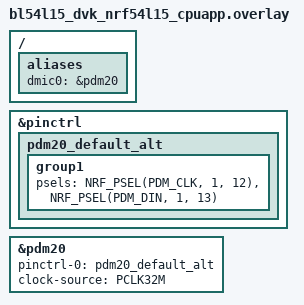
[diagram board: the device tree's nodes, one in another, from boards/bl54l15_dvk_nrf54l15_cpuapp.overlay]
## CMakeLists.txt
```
# SPDX-License-Identifier: Apache-2.0

cmake_minimum_required(VERSION 3.28.0)
find_package(Zephyr REQUIRED HINTS $ENV{ZEPHYR_BASE})
project(dmic_api)

FILE(GLOB app_sources src/*.c)
target_sources(app PRIVATE ${app_sources})
```

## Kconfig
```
# Copyright 2025 NXP
# SPDX-License-Identifier: Apache-2.0

source "Kconfig.zephyr"

config SAMPLE_BIT_WIDTH
	int "Sample bit width"
	default 32 if DT_HAS_NXP_MICFIL_ENABLED
	default 16
	help
	  PCM sample bit width.

config SAMPLE_PDM_CHANNELS
	int "Number of DMIC channels"
	default 4 if DT_HAS_NXP_MICFIL_ENABLED || DT_HAS_NXP_DMIC_ENABLED
	default 1 if DT_HAS_RENESAS_RA_PDM_ENABLED
	default 2
	help
	  Count of DMIC channels to capture and process. With 1, the stereo
	  test is skipped.

config TEST_HW_CHANNEL_INDEX
	int "hardware controller index"
	default 0
	help
	  Specifies the index of the hardware controller.

config TEST_SMALL_BUFFER
	bool "Use a smaller buffer for testing"
	default y if DT_HAS_RENESAS_RA_PDM_ENABLED
	help
	  Use a smaller buffer for testing. This is useful if your device has limited memory.
```

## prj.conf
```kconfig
CONFIG_TEST=y
CONFIG_ZTEST=y
CONFIG_AUDIO=y
CONFIG_AUDIO_DMIC=y

# Use deferred logging mode so the TC_PRINT calls while reading from DMIC
# do not block
CONFIG_LOG=y
CONFIG_LOG_MODE_DEFERRED=y
```

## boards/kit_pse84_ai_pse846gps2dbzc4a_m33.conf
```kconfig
# SPDX-FileCopyrightText: <text>Copyright (c) 2026 Infineon Technologies AG,
# or an affiliate of Infineon Technologies AG. All rights reserved.</text>
#
# SPDX-License-Identifier: Apache-2.0

CONFIG_TEST_HW_CHANNEL_INDEX=1
CONFIG_TEST_SMALL_BUFFER=y
```

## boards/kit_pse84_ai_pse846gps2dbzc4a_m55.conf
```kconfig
# SPDX-FileCopyrightText: Copyright (c) 2026 Infineon Technologies AG,
# SPDX-FileCopyrightText: or an affiliate of Infineon Technologies AG. All rights reserved.
#
# SPDX-License-Identifier: Apache-2.0

CONFIG_TEST_HW_CHANNEL_INDEX=1
```

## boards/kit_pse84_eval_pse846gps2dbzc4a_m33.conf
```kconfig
# SPDX-FileCopyrightText: Copyright (c) 2026 Infineon Technologies AG,
# SPDX-FileCopyrightText: or an affiliate of Infineon Technologies AG. All rights reserved.
#
# SPDX-License-Identifier: Apache-2.0

CONFIG_TEST_HW_CHANNEL_INDEX=1
CONFIG_TEST_SMALL_BUFFER=y
```

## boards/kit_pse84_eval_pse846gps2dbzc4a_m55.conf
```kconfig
# SPDX-FileCopyrightText: <text>Copyright (c) 2026 Infineon Technologies AG,
# or an affiliate of Infineon Technologies AG. All rights reserved.</text>
#
# SPDX-License-Identifier: Apache-2.0

CONFIG_TEST_HW_CHANNEL_INDEX=1
```

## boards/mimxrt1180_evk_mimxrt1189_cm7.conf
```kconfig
# SPDX-FileCopyrightText: Copyright 2026 NXP
# SPDX-License-Identifier: Apache-2.0

# The default buffers do not fit in the 256 KB DTCM
CONFIG_TEST_SMALL_BUFFER=y
```

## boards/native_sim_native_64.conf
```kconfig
# Copyright 2026 NXP
# SPDX-License-Identifier: Apache-2.0

CONFIG_AUDIO_DMIC_NATIVE_SIM=y
CONFIG_AUDIO_DMIC_NATIVE_SIM_FILE_PATH="/tmp/native_sim_dmic_in.pcm"
CONFIG_SAMPLE_BIT_WIDTH=16
CONFIG_SAMPLE_PDM_CHANNELS=2
CONFIG_TEST_HW_CHANNEL_INDEX=0
```

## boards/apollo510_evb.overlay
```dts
/*
 * Copyright (c) 2025 Ambiq Micro Inc.
 *
 * SPDX-License-Identifier: Apache-2.0
 */

/ {
	aliases {
		dmic-dev = &pdm0;
	};
};

&pdm0 {
	status = "okay";
};
```

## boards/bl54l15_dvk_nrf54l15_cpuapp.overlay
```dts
/*
 * Copyright (c) 2024 Nordic Semiconductor ASA
 * Copyright (c) 2025 Ezurio LLC
 *
 * SPDX-License-Identifier: Apache-2.0
 */

/ {
	aliases {
		dmic0 = &pdm20;
	};
};

&pinctrl {
	pdm20_default_alt: pdm20_default_alt {
		group1 {
			psels = <NRF_PSEL(PDM_CLK, 1, 12)>,
				<NRF_PSEL(PDM_DIN, 1, 13)>;
		};
	};
};

dmic_dev: &pdm20 {
	pinctrl-0 = <&pdm20_default_alt>;
	pinctrl-names = "default";
	clock-source = "PCLK32M";
	status = "okay";
};
```

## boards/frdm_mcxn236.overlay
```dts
/*
 * Copyright 2025 NXP
 *
 * SPDX-License-Identifier: Apache-2.0
 */

/ {
	aliases {
		dmic-dev = &pdm;
	};
};

&pdm {
	status = "okay";

	channel0: pdm-channel@0 {
		status = "okay";
	};

	channel1: pdm-channel@1 {
		status = "okay";
	};
};
```

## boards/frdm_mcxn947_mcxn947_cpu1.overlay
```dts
/*
 * SPDX-License-Identifier: Apache-2.0
 *
 * Copyright 2025 NXP
 */

/ {
	aliases {
		dmic-dev = &micfil;
	};
};

dmic_dev: &micfil {

	status = "okay";
	channel0: micfil-channel@0 {
		status = "okay";
	};
	channel1: micfil-channel@1 {
		status = "okay";
	};
};
```

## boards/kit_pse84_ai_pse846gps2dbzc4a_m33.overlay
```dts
/*
 * SPDX-FileCopyrightText: <text>Copyright (c) 2026 Infineon Technologies AG,
 * or an affiliate of Infineon Technologies AG. All rights reserved.</text>
 *
 * SPDX-License-Identifier: Apache-2.0
 */

#include "kit_pse84_common.overlay"
```

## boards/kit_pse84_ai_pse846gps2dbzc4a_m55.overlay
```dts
/*
 * SPDX-FileCopyrightText: Copyright (c) 2026 Infineon Technologies AG,
 * SPDX-FileCopyrightText: or an affiliate of Infineon Technologies AG. All rights reserved.
 *
 * SPDX-License-Identifier: Apache-2.0
 */

#include "kit_pse84_common.overlay"
```

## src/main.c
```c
/*
 * Copyright 2023 NXP
 *
 * SPDX-License-Identifier: Apache-2.0
 */

/*
 * Based on DMIC driver sample, which is:
 * Copyright (c) 2021 Nordic Semiconductor ASA
 */

#include <zephyr/kernel.h>
#include <zephyr/audio/audio_caps.h>
#include <zephyr/audio/dmic.h>
#include <zephyr/ztest.h>

static const struct device *dmic_dev = DEVICE_DT_GET(DT_ALIAS(dmic0));

#define SAMPLE_BIT_WIDTH CONFIG_SAMPLE_BIT_WIDTH
#define PDM_CHANNELS     CONFIG_SAMPLE_PDM_CHANNELS
#define PDM_CTL_IDX      CONFIG_TEST_HW_CHANNEL_INDEX
#define BYTES_PER_SAMPLE SAMPLE_BIT_WIDTH / 8
#define MAX_SAMPLE_RATE  48000

/* Milliseconds to wait for a block to be read. */
#define READ_TIMEOUT 1000
/* Size of a block for 100 ms of audio data. */
#if defined(CONFIG_COVERAGE) || defined(CONFIG_TEST_SMALL_BUFFER)
/* Use smaller buffer in coverage mode or if the device has limited memory. */
#define BLOCK_SIZE(_sample_rate, _number_of_channels) \
	(BYTES_PER_SAMPLE * (_sample_rate / 100) * _number_of_channels)
#else
#define BLOCK_SIZE(_sample_rate, _number_of_channels) \
	(BYTES_PER_SAMPLE * (_sample_rate / 10) * _number_of_channels)
#endif

/* Driver will allocate blocks from this slab to receive audio data into them.
 * Application, after getting a given block from the driver and processing its
 * data, needs to free that block.
 */
#define MAX_BLOCK_SIZE   BLOCK_SIZE(MAX_SAMPLE_RATE, PDM_CHANNELS)
#define BLOCK_COUNT      8

/* Cache-line align the blocks so cache maintenance on one block cannot
 * corrupt a neighbouring block
 */
#ifdef CONFIG_DCACHE_LINE_SIZE
#define SLAB_ALIGN MAX(4, CONFIG_DCACHE_LINE_SIZE)
#else
#define SLAB_ALIGN 4
#endif

K_MEM_SLAB_DEFINE_STATIC(mem_slab, MAX_BLOCK_SIZE, BLOCK_COUNT, SLAB_ALIGN);

static struct pcm_stream_cfg pcm_stream = {
	.pcm_width = SAMPLE_BIT_WIDTH,
	.mem_slab = &mem_slab,
};
static struct dmic_cfg dmic_cfg = {
	.io = {
		/* These fields can be used to limit the PDM clock
		 * configurations that the driver is allowed to use
		 * to those supported by the microphone.
		 */
		.min_pdm_clk_freq = 1000000,
		.max_pdm_clk_freq = 3500000,
		.min_pdm_clk_dc   = 40,
		.max_pdm_clk_dc   = 60,
	},
	.streams = &pcm_stream,
	.channel = {
		.req_num_streams = 1,
	},
};

/* Verify that dmic_trigger fails when DMIC is not configured
 * this test must run first, before DMIC has been configured
 */
ZTEST(dmic, test_0_start_fail)
{
	int ret;

	zassert_true(device_is_ready(dmic_dev), "DMIC device is not ready");
	ret = dmic_trigger(dmic_dev, DMIC_TRIGGER_START);
	zassert_not_equal(ret, 0, "DMIC trigger should fail when DMIC is not configured");
}

static int do_pdm_transfer(const struct device *dmic,
			    struct dmic_cfg *cfg)
{
	int ret;
	void *buffer;
	size_t size;

	TC_PRINT("PCM output rate: %u, channels: %u\n",
		 cfg->streams[0].pcm_rate, cfg->channel.req_num_chan);

	ret = dmic_configure(dmic, cfg);
	if (ret < 0) {
		TC_PRINT("DMIC configuration failed: %d\n", ret);
		return ret;
	}

	/* Check that the driver is properly populating the "act*" fields */
	zassert_equal(cfg->channel.act_num_chan,
		      cfg->channel.req_num_chan,
		      "DMIC configure should populate act_num_chan field");
	zassert_equal(cfg->channel.act_chan_map_lo,
		      cfg->channel.req_chan_map_lo,
		      "DMIC configure should populate act_chan_map_lo field");
	zassert_equal(cfg->channel.act_chan_map_hi,
		      cfg->channel.req_chan_map_hi,
		      "DMIC configure should populate act_chan_map_hi field");
	ret = dmic_trigger(dmic, DMIC_TRIGGER_START);
	if (ret < 0) {
		TC_PRINT("DMIC start trigger failed: %d\n", ret);
		return ret;
	}

	/* We read more than the total BLOCK_COUNT to insure the DMIC
	 * driver correctly reallocates memory slabs as it exhausts existing
	 * ones.
	 */
	for (int i = 0; i < (2 * BLOCK_COUNT); i++) {
		ret = dmic_read(dmic, 0, &buffer, &size, READ_TIMEOUT);
		if (ret < 0) {
			TC_PRINT("DMIC read failed: %d\n", ret);
			return ret;
		}

		TC_PRINT("%d - got buffer %p of %u bytes\n", i, buffer, size);
		k_mem_slab_free(&mem_slab, buffer);
	}

	ret = dmic_trigger(dmic, DMIC_TRIGGER_STOP);
	if (ret < 0) {
		TC_PRINT("DMIC stop trigger failed: %d\n", ret);
		return ret;
	}
	return 0;
}


/* Verify that the DMIC can transfer from a single channel */
ZTEST(dmic, test_single_channel)
{
	dmic_cfg.channel.req_num_chan = 1;
	dmic_cfg.channel.req_chan_map_lo =
		dmic_build_channel_map(0, PDM_CTL_IDX, PDM_CHAN_LEFT);
	dmic_cfg.streams[0].pcm_rate = MAX_SAMPLE_RATE;
	dmic_cfg.streams[0].block_size =
		BLOCK_SIZE(dmic_cfg.streams[0].pcm_rate,
			   dmic_cfg.channel.req_num_chan);
	zassert_equal(do_pdm_transfer(dmic_dev, &dmic_cfg), 0,
		      "Single channel transfer failed");
}

/* Verify that the DMIC can transfer from a L/R channel pair */
ZTEST(dmic, test_stereo_channel)
{
	if (PDM_CHANNELS < 2) {
		ztest_test_skip();
	}

	dmic_cfg.channel.req_num_chan = 2;
	dmic_cfg.channel.req_chan_map_lo =
		dmic_build_channel_map(0, PDM_CTL_IDX, PDM_CHAN_LEFT) |
		dmic_build_channel_map(1, PDM_CTL_IDX, PDM_CHAN_RIGHT);
	dmic_cfg.streams[0].pcm_rate = MAX_SAMPLE_RATE;
	dmic_cfg.streams[0].block_size =
		BLOCK_SIZE(dmic_cfg.streams[0].pcm_rate,
			   dmic_cfg.channel.req_num_chan);
	zassert_equal(do_pdm_transfer(dmic_dev, &dmic_cfg), 0,
		      "L/R channel transfer failed");
	dmic_cfg.channel.req_chan_map_lo =
		dmic_build_channel_map(0, PDM_CTL_IDX, PDM_CHAN_RIGHT) |
		dmic_build_channel_map(1, PDM_CTL_IDX, PDM_CHAN_LEFT);

	zassert_equal(do_pdm_transfer(dmic_dev, &dmic_cfg), 0,
		      "R/L channel transfer failed");
}

/* Test DMIC with maximum number of channels */
ZTEST(dmic, test_max_channel)
{
	enum pdm_lr lr;
	uint8_t pdm_hw_chan;

	dmic_cfg.channel.req_num_chan = PDM_CHANNELS;
	dmic_cfg.channel.req_chan_map_lo = 0;
	dmic_cfg.channel.req_chan_map_hi = 0;
	for (uint8_t i = 0; i < PDM_CHANNELS; i++) {
		lr = ((i % 2) == 0) ? PDM_CHAN_LEFT : PDM_CHAN_RIGHT;
		pdm_hw_chan = PDM_CTL_IDX + (i >> 1);
		if (i < 4) {
			dmic_cfg.channel.req_chan_map_lo |=
				dmic_build_channel_map(i, pdm_hw_chan, lr);
		} else {
			dmic_cfg.channel.req_chan_map_hi |=
				dmic_build_channel_map(i, pdm_hw_chan, lr);
		}
	}

	dmic_cfg.streams[0].pcm_rate = MAX_SAMPLE_RATE;
	dmic_cfg.streams[0].block_size =
		BLOCK_SIZE(dmic_cfg.streams[0].pcm_rate,
			   dmic_cfg.channel.req_num_chan);
	zassert_equal(do_pdm_transfer(dmic_dev, &dmic_cfg), 0,
		      "Maximum channel transfer failed");
}

/* Test pausing and restarting a channel */
ZTEST(dmic, test_pause_restart)
{
	int ret, i;
	void *buffer;
	size_t size;

	dmic_cfg.channel.req_num_chan = 1;
	dmic_cfg.channel.req_chan_map_lo =
		dmic_build_channel_map(0, PDM_CTL_IDX, PDM_CHAN_LEFT);
	dmic_cfg.streams[0].pcm_rate = MAX_SAMPLE_RATE;
	dmic_cfg.streams[0].block_size =
		BLOCK_SIZE(dmic_cfg.streams[0].pcm_rate,
			   dmic_cfg.channel.req_num_chan);
	ret = dmic_configure(dmic_dev, &dmic_cfg);
	zassert_equal(ret, 0, "DMIC configure failed");

	/* Start the DMIC, and pause it immediately */
	ret = dmic_trigger(dmic_dev, DMIC_TRIGGER_START);
	zassert_equal(ret, 0, "DMIC start failed");
	ret = dmic_trigger(dmic_dev, DMIC_TRIGGER_PAUSE);
	zassert_equal(ret, 0, "DMIC pause failed");
	/* There may be some buffers in the DMIC queue, but a read
	 * should eventually time out while it is paused
	 */
	for (i = 0; i < (2 * BLOCK_COUNT); i++) {
		ret = dmic_read(dmic_dev, 0, &buffer, &size, READ_TIMEOUT);
		if (ret < 0) {
			break;
		}
		k_mem_slab_free(&mem_slab, buffer);
	}
	zassert_not_equal(ret, 0, "DMIC is paused, reads should timeout");
	TC_PRINT("Queue drained after %d reads\n", i);
	/* Unpause the DMIC */
	ret = dmic_trigger(dmic_dev, DMIC_TRIGGER_RELEASE);
	zassert_equal(ret, 0, "DMIC release failed");
	/* Reads should not timeout now */
	for (i = 0; i < (2 * BLOCK_COUNT); i++) {
		ret = dmic_read(dmic_dev, 0, &buffer, &size, READ_TIMEOUT);
		if (ret < 0) {
			break;
		}
		k_mem_slab_free(&mem_slab, buffer);
	}
	zassert_equal(ret, 0, "DMIC is active, reads should succeed");
	TC_PRINT("%d reads completed\n", (2 * BLOCK_COUNT));
	/* Stop the DMIC, and repeat the same tests */
	ret = dmic_trigger(dmic_dev, DMIC_TRIGGER_STOP);
	zassert_equal(ret, 0, "DMIC stop failed");
	/* Versus a pause, DMIC reads should immediately stop once DMIC times
	 * out
	 */
	ret = dmic_read(dmic_dev, 0, &buffer, &size, READ_TIMEOUT);
	zassert_not_equal(ret, 0, "DMIC read should timeout when DMIC is stopped");
	ret = dmic_trigger(dmic_dev, DMIC_TRIGGER_START);
	zassert_equal(ret, 0, "DMIC restart failed");
	/* Reads should not timeout now */
	for (i = 0; i < (2 * BLOCK_COUNT); i++) {
		ret = dmic_read(dmic_dev, 0, &buffer, &size, READ_TIMEOUT);
		if (ret < 0) {
			break;
		}
		k_mem_slab_free(&mem_slab, buffer);
	}
	zassert_equal(ret, 0, "DMIC is active, reads should succeed");
	TC_PRINT("%d reads completed\n", (2 * BLOCK_COUNT));
	/* Test is over. Stop the DMIC */
	ret = dmic_trigger(dmic_dev, DMIC_TRIGGER_STOP);
	zassert_equal(ret, 0, "DMIC stop failed");
}

/* Verify that channel map without adjacent L/R pairs fails */
ZTEST(dmic, test_bad_pair)
{
	int ret;

	dmic_cfg.channel.req_num_chan = 2;
	dmic_cfg.channel.req_chan_map_lo =
		dmic_build_channel_map(0, 0, PDM_CHAN_RIGHT) |
		dmic_build_channel_map(1, 0, PDM_CHAN_RIGHT);
	dmic_cfg.streams[0].pcm_rate = MAX_SAMPLE_RATE;
	dmic_cfg.streams[0].block_size =
		BLOCK_SIZE(dmic_cfg.streams[0].pcm_rate,
			   dmic_cfg.channel.req_num_chan);
	ret = dmic_configure(dmic_dev, &dmic_cfg);
	zassert_not_equal(ret, 0, "DMIC configure should fail with "
			  "two of same channel in map");

	dmic_cfg.channel.req_num_chan = 2;
	dmic_cfg.channel.req_chan_map_lo =
		dmic_build_channel_map(0, 0, PDM_CHAN_RIGHT) |
		dmic_build_channel_map(1, 1, PDM_CHAN_LEFT);
	ret = dmic_configure(dmic_dev, &dmic_cfg);
	zassert_not_equal(ret, 0, "DMIC configure should fail with "
			  "non adjacent channels in map");
}

/**
 * @brief Test the dmic_get_caps API function
 *
 * This test validates the DMIC get_caps API functionality by testing both
 * successful operation and error handling scenarios.
 */
ZTEST(dmic, test_get_caps)
{
	int ret;
	struct audio_caps caps;

	zassert_true(device_is_ready(dmic_dev), "DMIC device is not ready");

	/**
	 * Test Case 1: Normal operation - Valid parameters
	 * Expected: Function should return 0 (success) or -ENOSYS (not implemented)
	 */
	ret = dmic_get_caps(dmic_dev, &caps);

	/* Handle case where driver doesn't implement get_caps */
	if (ret == -ENOSYS) {
		TC_PRINT("DMIC get_caps not implemented by driver\n");
		ztest_test_skip();
		return;
	}

	/* Verify successful execution */
	zassert_equal(ret, 0, "dmic_get_caps should return 0, got %d", ret);

	/**
	 * Test Case 2: Capability value validation
	 * Verify that returned capability values are within reasonable ranges
	 */
	zassert_true(caps.min_total_channels >= 1, "min_total_channels should be >= 1, got %d",
		     caps.min_total_channels);

	zassert_true(caps.max_total_channels >= caps.min_total_channels,
		     "max_total_channels (%u) should be >= min_total_channels (%u)",
		     caps.max_total_channels, caps.min_total_channels);

	zassert_not_equal(caps.supported_sample_rates, 0, "supported_sample_rates should not be 0");

	zassert_not_equal(caps.supported_bit_widths, 0, "supported_bit_widths should not be 0");

	zassert_true(caps.min_num_buffers >= 1, "min_num_buffers should be >= 1, got %u",
		     caps.min_num_buffers);

	zassert_true(caps.max_frame_interval >= caps.min_frame_interval,
		     "max_frame_interval (%u) should be >= min_frame_interval (%u)",
		     caps.max_frame_interval, caps.min_frame_interval);

	/**
	 * Test Case 3: Error handling - NULL caps pointer
	 * Expected: Function should return -EINVAL for invalid parameter
	 */
	ret = dmic_get_caps(dmic_dev, NULL);
	zassert_equal(ret, -EINVAL,
		      "dmic_get_caps should return -EINVAL for NULL caps pointer, got %d", ret);
}

/**
 * @brief Verify that the DMIC can capture using the reported maximum channel count
 *
 * A driver that reports more channels than it can configure, or than are
 * enabled in devicetree, fails here.
 */
ZTEST(dmic, test_get_caps_max_channels)
{
	const uint32_t pcm_rate = 16000;
	struct audio_caps caps;
	uint32_t frame_bytes;
	uint32_t block_size;
	enum pdm_lr lr;
	int ret;

	ret = dmic_get_caps(dmic_dev, &caps);
	if (ret == -ENOSYS) {
		ztest_test_skip();
		return;
	}
	zassert_equal(ret, 0, "dmic_get_caps failed: %d", ret);
	zassert_true(caps.max_total_channels >= 1, "No channels reported");

	if ((caps.supported_sample_rates & AUDIO_SAMPLE_RATE_16000) == 0U) {
		TC_PRINT("16 kHz not reported as supported, skipping\n");
		ztest_test_skip();
		return;
	}

	dmic_cfg.channel.req_num_chan = caps.max_total_channels;
	dmic_cfg.channel.req_chan_map_lo = 0;
	dmic_cfg.channel.req_chan_map_hi = 0;
	for (uint8_t i = 0; i < caps.max_total_channels; i++) {
		lr = ((i % 2) == 0) ? PDM_CHAN_LEFT : PDM_CHAN_RIGHT;
		if (i < 8) {
			dmic_cfg.channel.req_chan_map_lo |=
				dmic_build_channel_map(i, PDM_CTL_IDX + (i >> 1), lr);
		} else {
			dmic_cfg.channel.req_chan_map_hi |=
				dmic_build_channel_map(i, PDM_CTL_IDX + (i >> 1), lr);
		}
	}

	/* Keep the block within the test slab while staying frame aligned */
	frame_bytes = BYTES_PER_SAMPLE * caps.max_total_channels;
	block_size = MIN(BLOCK_SIZE(pcm_rate, caps.max_total_channels),
			 (MAX_BLOCK_SIZE / frame_bytes) * frame_bytes);

	dmic_cfg.streams[0].pcm_rate = pcm_rate;
	dmic_cfg.streams[0].block_size = block_size;
	zassert_equal(do_pdm_transfer(dmic_dev, &dmic_cfg), 0,
		      "Transfer with reported max_total_channels (%u) failed",
		      caps.max_total_channels);
}

ZTEST_SUITE(dmic, NULL, NULL, NULL, NULL, NULL);
```
